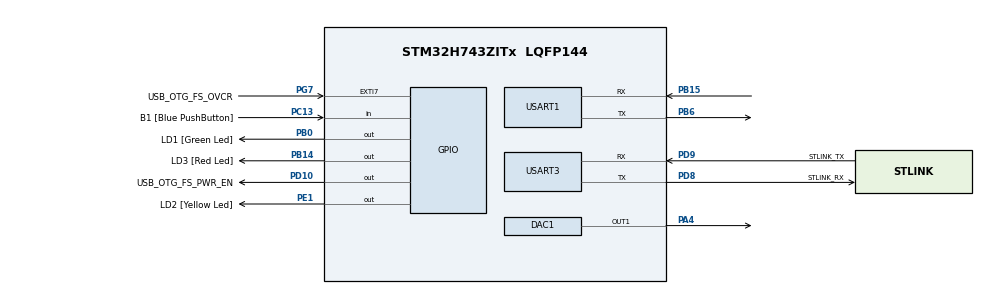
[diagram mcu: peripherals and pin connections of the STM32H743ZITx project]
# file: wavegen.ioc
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CORTEX_M7.CPU_DCache=Enabled
CORTEX_M7.CPU_ICache=Enabled
DAC1.DAC_Trigger-DAC_OUT1=DAC_TRIGGER_T6_TRGO
Dma.DAC1_CH1.0.Direction=DMA_MEMORY_TO_PERIPH
Dma.DAC1_CH1.0.EventEnable=DISABLE
Dma.DAC1_CH1.0.FIFOMode=DMA_FIFOMODE_DISABLE
Dma.DAC1_CH1.0.Instance=DMA1_Stream0
Dma.DAC1_CH1.0.MemDataAlignment=DMA_MDATAALIGN_HALFWORD
Dma.DAC1_CH1.0.MemInc=DMA_MINC_ENABLE
Dma.DAC1_CH1.0.Mode=DMA_CIRCULAR
Dma.DAC1_CH1.0.PeriphDataAlignment=DMA_PDATAALIGN_HALFWORD
Dma.DAC1_CH1.0.PeriphInc=DMA_PINC_DISABLE
Dma.DAC1_CH1.0.Polarity=HAL_DMAMUX_REQ_GEN_RISING
Dma.DAC1_CH1.0.Priority=DMA_PRIORITY_LOW
Dma.DAC1_CH1.0.RequestNumber=1
Dma.DAC1_CH1.0.SignalID=NONE
Dma.DAC1_CH1.0.SyncEnable=DISABLE
Dma.DAC1_CH1.0.SyncPolarity=HAL_DMAMUX_SYNC_NO_EVENT
Dma.DAC1_CH1.0.SyncRequestNumber=1
Dma.DAC1_CH1.0.SyncSignalID=NONE
Dma.Request0=DAC1_CH1
Mcu.Family=STM32H7
Mcu.Name=STM32H743ZITx
Mcu.Package=LQFP144
NVIC.DMA1_Stream0_IRQn=true\:0\:0\:false\:false\:true\:false\:true
NVIC.PriorityGroup=NVIC_PRIORITYGROUP_4
NVIC.TIM2_IRQn=true\:0\:0\:false\:false\:true\:false\:true
NVIC.TimeBase=TIM2_IRQn
NVIC.TimeBaseIP=TIM2
PA1.Signal=ETH_REF_CLK
PA11.Signal=USB_OTG_FS_DM
PA12.Signal=USB_OTG_FS_DP
PA2.Signal=ETH_MDIO
PA4.Signal=COMP_DAC11_group
PA7.Signal=ETH_CRS_DV
PA8.Signal=USB_OTG_FS_SOF
PA9.Signal=USB_OTG_FS_VBUS
PB0.GPIO_Label=LD1 [Green Led]
PB0.Signal=GPIO_Output
PB13.Signal=ETH_TXD1
PB14.GPIO_Label=LD3 [Red Led]
PB14.Signal=GPIO_Output
PB15.Mode=Asynchronous
PB15.Signal=USART1_RX
PB6.Mode=Asynchronous
PB6.Signal=USART1_TX
PC1.Signal=ETH_MDC
PC13.GPIO_Label=B1 [Blue PushButton]
PC13.Signal=GPIO_Input
PC14-OSC32_IN\ (OSC32_IN).Signal=RCC_OSC32_IN
PC15-OSC32_OUT\ (OSC32_OUT).Signal=RCC_OSC32_OUT
PC4.Signal=ETH_RXD0
PC5.Signal=ETH_RXD1
PD10.GPIO_Label=USB_OTG_FS_PWR_EN
PD10.Signal=GPIO_Output
PD8.GPIO_Label=STLINK_RX
PD8.Mode=Asynchronous
PD8.Signal=USART3_TX
PD9.GPIO_Label=STLINK_TX
PD9.Mode=Asynchronous
PD9.Signal=USART3_RX
PE1.GPIO_Label=LD2 [Yellow Led]
PE1.Signal=GPIO_Output
PG11.Signal=ETH_TX_EN
PG13.Signal=ETH_TXD0
PG7.GPIO_Label=USB_OTG_FS_OVCR
PG7.Signal=GPXTI7
PH0-OSC_IN\ (PH0).Mode=HSE-External-Clock-Source
PH0-OSC_IN\ (PH0).Signal=RCC_OSC_IN
PH1-OSC_OUT\ (PH1).Signal=RCC_OSC_OUT
ProjectManager.HeapSize=0x200
ProjectManager.StackSize=0x400
ProjectManager.TargetToolchain=STM32CubeIDE
RCC.ADCFreq_Value=16125000
RCC.APB1Freq_Value=100000000
RCC.APB2Freq_Value=100000000
RCC.APB3Freq_Value=100000000
RCC.APB4Freq_Value=100000000
RCC.CortexFreq_Value=400000000
RCC.D1PPRE=RCC_APB3_DIV2
RCC.D2PPRE1=RCC_APB1_DIV2
RCC.D2PPRE2=RCC_APB2_DIV2
RCC.D3PPRE=RCC_APB4_DIV2
RCC.DIVM1=4
RCC.DIVN1=400
RCC.HCLKFreq_Value=200000000
RCC.HPRE=RCC_HCLK_DIV2
RCC.HSE_VALUE=8000000
RCC.PLLSourceVirtual=RCC_PLLSOURCE_HSE
RCC.SYSCLKFreq_VALUE=400000000
RCC.SYSCLKSource=RCC_SYSCLKSOURCE_PLLCLK
RCC.USBFreq_Value=400000000
SH.COMP_DAC11_group.0=DAC1_OUT1,DAC_OUT1
TIM6.AutoReloadPreload=TIM_AUTORELOAD_PRELOAD_ENABLE
TIM6.Period=1999
TIM6.TIM_MasterOutputTrigger=TIM_TRGO_UPDATE
USART1.VirtualMode-Asynchronous=VM_ASYNC
USART3.VirtualMode-Asynchronous=VM_ASYNC
VP_SYS_VS_tim2.Mode=TIM2
VP_TIM6_VS_ClockSourceINT.Mode=Enable_Timer
board=NUCLEO-H743ZI2

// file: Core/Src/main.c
/* USER CODE BEGIN Header */
/**
  ******************************************************************************
  * @file           : main.c
  * @brief          : Main program body
  ******************************************************************************
  * @attention
  *
  * <h2><center>&copy; Copyright (c) 2020 STMicroelectronics.
  * All rights reserved.</center></h2>
  *
  * This software component is licensed by ST under BSD 3-Clause license,
  * the "License"; You may not use this file except in compliance with the
  * License. You may obtain a copy of the License at:
  *                        opensource.org/licenses/BSD-3-Clause
  *
  ******************************************************************************
  */
/* USER CODE END Header */
#include "main.h"

/* USER CODE BEGIN Includes */
#include "output.h"
#include "waves.h"
/* USER CODE END Includes */

/* USER CODE BEGIN PD */
#define WELCOME_MESSAGE			"\r\n\nDAC Waveform Project\r\n\n"
/* USER CODE END PD */

DAC_HandleTypeDef hdac1;
DMA_HandleTypeDef hdma_dac1_ch1;

TIM_HandleTypeDef htim6;

UART_HandleTypeDef huart1;
UART_HandleTypeDef huart3;

void SystemClock_Config(void);
static void MX_GPIO_Init(void);
static void MX_DMA_Init(void);
static void MX_DAC1_Init(void);
static void MX_TIM6_Init(void);
static void MX_USART1_UART_Init(void);
static void MX_USART3_UART_Init(void);

int main(void)
{

  /* Enable I-Cache---------------------------------------------------------*/
  SCB_EnableICache();

  /* Enable D-Cache---------------------------------------------------------*/
  SCB_EnableDCache();

  /* MCU Configuration--------------------------------------------------------*/

  /* Reset of all peripherals, Initializes the Flash interface and the Systick. */
  HAL_Init();

  /* Configure the system clock */
  SystemClock_Config();

  /* Initialize all configured peripherals */
  MX_GPIO_Init();
  MX_DMA_Init();
  MX_DAC1_Init();
  MX_TIM6_Init();
  MX_USART1_UART_Init();
  MX_USART3_UART_Init();
  /* USER CODE BEGIN 2 */
  output (WELCOME_MESSAGE);
  /* USER CODE END 2 */

  /* Infinite loop */
  /* USER CODE BEGIN WHILE */
  //cosine_test();
  waveforms();

  while (1)
  {
    /* USER CODE END WHILE */

  }
}

void SystemClock_Config(void)
{
  RCC_OscInitTypeDef RCC_OscInitStruct = {0};
  RCC_ClkInitTypeDef RCC_ClkInitStruct = {0};
  RCC_PeriphCLKInitTypeDef PeriphClkInitStruct = {0};

  /** Supply configuration update enable
  */
  HAL_PWREx_ConfigSupply(PWR_LDO_SUPPLY);
  /** Configure the main internal regulator output voltage
  */
  __HAL_PWR_VOLTAGESCALING_CONFIG(PWR_REGULATOR_VOLTAGE_SCALE1);

  while(!__HAL_PWR_GET_FLAG(PWR_FLAG_VOSRDY)) {}
  /** Initializes the RCC Oscillators according to the specified parameters
  * in the RCC_OscInitTypeDef structure.
  */
  RCC_OscInitStruct.OscillatorType = RCC_OSCILLATORTYPE_HSE;
  RCC_OscInitStruct.HSEState = RCC_HSE_BYPASS;
  RCC_OscInitStruct.PLL.PLLState = RCC_PLL_ON;
  RCC_OscInitStruct.PLL.PLLSource = RCC_PLLSOURCE_HSE;
  RCC_OscInitStruct.PLL.PLLM = 4;
  RCC_OscInitStruct.PLL.PLLN = 400;
  RCC_OscInitStruct.PLL.PLLP = 2;
  RCC_OscInitStruct.PLL.PLLQ = 2;
  RCC_OscInitStruct.PLL.PLLR = 2;
  RCC_OscInitStruct.PLL.PLLRGE = RCC_PLL1VCIRANGE_1;
  RCC_OscInitStruct.PLL.PLLVCOSEL = RCC_PLL1VCOWIDE;
  RCC_OscInitStruct.PLL.PLLFRACN = 0;
  if (HAL_RCC_OscConfig(&RCC_OscInitStruct) != HAL_OK)
  {
    Error_Handler();
  }
  /** Initializes the CPU, AHB and APB buses clocks
  */
  RCC_ClkInitStruct.ClockType = RCC_CLOCKTYPE_HCLK|RCC_CLOCKTYPE_SYSCLK
                              |RCC_CLOCKTYPE_PCLK1|RCC_CLOCKTYPE_PCLK2
                              |RCC_CLOCKTYPE_D3PCLK1|RCC_CLOCKTYPE_D1PCLK1;
  RCC_ClkInitStruct.SYSCLKSource = RCC_SYSCLKSOURCE_PLLCLK;
  RCC_ClkInitStruct.SYSCLKDivider = RCC_SYSCLK_DIV1;
  RCC_ClkInitStruct.AHBCLKDivider = RCC_HCLK_DIV2;
  RCC_ClkInitStruct.APB3CLKDivider = RCC_APB3_DIV2;
  RCC_ClkInitStruct.APB1CLKDivider = RCC_APB1_DIV2;
  RCC_ClkInitStruct.APB2CLKDivider = RCC_APB2_DIV2;
  RCC_ClkInitStruct.APB4CLKDivider = RCC_APB4_DIV2;

  if (HAL_RCC_ClockConfig(&RCC_ClkInitStruct, FLASH_LATENCY_2) != HAL_OK)
  {
    Error_Handler();
  }
  PeriphClkInitStruct.PeriphClockSelection = RCC_PERIPHCLK_USART3|RCC_PERIPHCLK_USART1;
  PeriphClkInitStruct.Usart234578ClockSelection = RCC_USART234578CLKSOURCE_D2PCLK1;
  PeriphClkInitStruct.Usart16ClockSelection = RCC_USART16CLKSOURCE_D2PCLK2;
  if (HAL_RCCEx_PeriphCLKConfig(&PeriphClkInitStruct) != HAL_OK)
  {
    Error_Handler();
  }
}

static void MX_DAC1_Init(void)
{

  DAC_ChannelConfTypeDef sConfig = {0};

  /** DAC Initialization
  */
  hdac1.Instance = DAC1;
  if (HAL_DAC_Init(&hdac1) != HAL_OK)
  {
    Error_Handler();
  }
  /** DAC channel OUT1 config
  */
  sConfig.DAC_SampleAndHold = DAC_SAMPLEANDHOLD_DISABLE;
  sConfig.DAC_Trigger = DAC_TRIGGER_T6_TRGO;
  sConfig.DAC_OutputBuffer = DAC_OUTPUTBUFFER_ENABLE;
  sConfig.DAC_ConnectOnChipPeripheral = DAC_CHIPCONNECT_DISABLE;
  sConfig.DAC_UserTrimming = DAC_TRIMMING_FACTORY;
  if (HAL_DAC_ConfigChannel(&hdac1, &sConfig, DAC_CHANNEL_1) != HAL_OK)
  {
    Error_Handler();
  }

}

static void MX_TIM6_Init(void)
{

  TIM_MasterConfigTypeDef sMasterConfig = {0};

  htim6.Instance = TIM6;
  htim6.Init.Prescaler = 0;
  htim6.Init.CounterMode = TIM_COUNTERMODE_UP;
  htim6.Init.Period = 1999;
  htim6.Init.AutoReloadPreload = TIM_AUTORELOAD_PRELOAD_ENABLE;
  if (HAL_TIM_Base_Init(&htim6) != HAL_OK)
  {
    Error_Handler();
  }
  sMasterConfig.MasterOutputTrigger = TIM_TRGO_UPDATE;
  sMasterConfig.MasterSlaveMode = TIM_MASTERSLAVEMODE_DISABLE;
  if (HAL_TIMEx_MasterConfigSynchronization(&htim6, &sMasterConfig) != HAL_OK)
  {
    Error_Handler();
  }
  /* USER CODE BEGIN TIM6_Init 2 */
  /*##-2- Enable TIM peripheral counter ######################################*/
  HAL_TIM_Base_Start (&htim6);
  /* USER CODE END TIM6_Init 2 */

}

static void MX_USART1_UART_Init(void)
{

  huart1.Instance = USART1;
  huart1.Init.BaudRate = 115200;
  huart1.Init.WordLength = UART_WORDLENGTH_8B;
  huart1.Init.StopBits = UART_STOPBITS_1;
  huart1.Init.Parity = UART_PARITY_NONE;
  huart1.Init.Mode = UART_MODE_TX_RX;
  huart1.Init.HwFlowCtl = UART_HWCONTROL_NONE;
  huart1.Init.OverSampling = UART_OVERSAMPLING_16;
  huart1.Init.OneBitSampling = UART_ONE_BIT_SAMPLE_DISABLE;
  huart1.Init.ClockPrescaler = UART_PRESCALER_DIV1;
  huart1.AdvancedInit.AdvFeatureInit = UART_ADVFEATURE_NO_INIT;
  if (HAL_UART_Init(&huart1) != HAL_OK)
  {
    Error_Handler();
  }
  if (HAL_UARTEx_SetTxFifoThreshold(&huart1, UART_TXFIFO_THRESHOLD_1_8) != HAL_OK)
  {
    Error_Handler();
  }
  if (HAL_UARTEx_SetRxFifoThreshold(&huart1, UART_RXFIFO_THRESHOLD_1_8) != HAL_OK)
  {
    Error_Handler();
  }
  if (HAL_UARTEx_DisableFifoMode(&huart1) != HAL_OK)
  {
    Error_Handler();
  }

}

static void MX_USART3_UART_Init(void)
{

  huart3.Instance = USART3;
  huart3.Init.BaudRate = 115200;
  huart3.Init.WordLength = UART_WORDLENGTH_8B;
  huart3.Init.StopBits = UART_STOPBITS_1;
  huart3.Init.Parity = UART_PARITY_NONE;
  huart3.Init.Mode = UART_MODE_TX_RX;
  huart3.Init.HwFlowCtl = UART_HWCONTROL_NONE;
  huart3.Init.OverSampling = UART_OVERSAMPLING_16;
  huart3.Init.OneBitSampling = UART_ONE_BIT_SAMPLE_DISABLE;
  huart3.Init.ClockPrescaler = UART_PRESCALER_DIV1;
  huart3.AdvancedInit.AdvFeatureInit = UART_ADVFEATURE_NO_INIT;
  if (HAL_UART_Init(&huart3) != HAL_OK)
  {
    Error_Handler();
  }
  if (HAL_UARTEx_SetTxFifoThreshold(&huart3, UART_TXFIFO_THRESHOLD_1_8) != HAL_OK)
  {
    Error_Handler();
  }
  if (HAL_UARTEx_SetRxFifoThreshold(&huart3, UART_RXFIFO_THRESHOLD_1_8) != HAL_OK)
  {
    Error_Handler();
  }
  if (HAL_UARTEx_DisableFifoMode(&huart3) != HAL_OK)
  {
    Error_Handler();
  }

}

static void MX_DMA_Init(void)
{

  /* DMA controller clock enable */
  __HAL_RCC_DMA1_CLK_ENABLE();

  /* DMA interrupt init */
  /* DMA1_Stream0_IRQn interrupt configuration */
  HAL_NVIC_SetPriority(DMA1_Stream0_IRQn, 0, 0);
  HAL_NVIC_EnableIRQ(DMA1_Stream0_IRQn);

}

static void MX_GPIO_Init(void)
{
  GPIO_InitTypeDef GPIO_InitStruct = {0};

  /* GPIO Ports Clock Enable */
  __HAL_RCC_GPIOC_CLK_ENABLE();
  __HAL_RCC_GPIOH_CLK_ENABLE();
  __HAL_RCC_GPIOA_CLK_ENABLE();
  __HAL_RCC_GPIOB_CLK_ENABLE();
  __HAL_RCC_GPIOD_CLK_ENABLE();
  __HAL_RCC_GPIOG_CLK_ENABLE();
  __HAL_RCC_GPIOE_CLK_ENABLE();

  /*Configure GPIO pin Output Level */
  HAL_GPIO_WritePin(GPIOB, LD1_Pin|LD3_Pin, GPIO_PIN_RESET);

  /*Configure GPIO pin Output Level */
  HAL_GPIO_WritePin(USB_OTG_FS_PWR_EN_GPIO_Port, USB_OTG_FS_PWR_EN_Pin, GPIO_PIN_RESET);

  /*Configure GPIO pin Output Level */
  HAL_GPIO_WritePin(LD2_GPIO_Port, LD2_Pin, GPIO_PIN_RESET);

  /*Configure GPIO pin : B1_Pin */
  GPIO_InitStruct.Pin = B1_Pin;
  GPIO_InitStruct.Mode = GPIO_MODE_INPUT;
  GPIO_InitStruct.Pull = GPIO_NOPULL;
  HAL_GPIO_Init(B1_GPIO_Port, &GPIO_InitStruct);

  /*Configure GPIO pins : PC1 PC4 PC5 */
  GPIO_InitStruct.Pin = GPIO_PIN_1|GPIO_PIN_4|GPIO_PIN_5;
  GPIO_InitStruct.Mode = GPIO_MODE_AF_PP;
  GPIO_InitStruct.Pull = GPIO_NOPULL;
  GPIO_InitStruct.Speed = GPIO_SPEED_FREQ_LOW;
  GPIO_InitStruct.Alternate = GPIO_AF11_ETH;
  HAL_GPIO_Init(GPIOC, &GPIO_InitStruct);

  /*Configure GPIO pins : PA1 PA2 PA7 */
  GPIO_InitStruct.Pin = GPIO_PIN_1|GPIO_PIN_2|GPIO_PIN_7;
  GPIO_InitStruct.Mode = GPIO_MODE_AF_PP;
  GPIO_InitStruct.Pull = GPIO_NOPULL;
  GPIO_InitStruct.Speed = GPIO_SPEED_FREQ_LOW;
  GPIO_InitStruct.Alternate = GPIO_AF11_ETH;
  HAL_GPIO_Init(GPIOA, &GPIO_InitStruct);

  /*Configure GPIO pins : LD1_Pin LD3_Pin */
  GPIO_InitStruct.Pin = LD1_Pin|LD3_Pin;
  GPIO_InitStruct.Mode = GPIO_MODE_OUTPUT_PP;
  GPIO_InitStruct.Pull = GPIO_NOPULL;
  GPIO_InitStruct.Speed = GPIO_SPEED_FREQ_LOW;
  HAL_GPIO_Init(GPIOB, &GPIO_InitStruct);

  /*Configure GPIO pin : PB13 */
  GPIO_InitStruct.Pin = GPIO_PIN_13;
  GPIO_InitStruct.Mode = GPIO_MODE_AF_PP;
  GPIO_InitStruct.Pull = GPIO_NOPULL;
  GPIO_InitStruct.Speed = GPIO_SPEED_FREQ_LOW;
  GPIO_InitStruct.Alternate = GPIO_AF11_ETH;
  HAL_GPIO_Init(GPIOB, &GPIO_InitStruct);

  /*Configure GPIO pin : USB_OTG_FS_PWR_EN_Pin */
  GPIO_InitStruct.Pin = USB_OTG_FS_PWR_EN_Pin;
  GPIO_InitStruct.Mode = GPIO_MODE_OUTPUT_PP;
  GPIO_InitStruct.Pull = GPIO_NOPULL;
  GPIO_InitStruct.Speed = GPIO_SPEED_FREQ_LOW;
  HAL_GPIO_Init(USB_OTG_FS_PWR_EN_GPIO_Port, &GPIO_InitStruct);

  /*Configure GPIO pin : USB_OTG_FS_OVCR_Pin */
  GPIO_InitStruct.Pin = USB_OTG_FS_OVCR_Pin;
  GPIO_InitStruct.Mode = GPIO_MODE_IT_RISING;
  GPIO_InitStruct.Pull = GPIO_NOPULL;
  HAL_GPIO_Init(USB_OTG_FS_OVCR_GPIO_Port, &GPIO_InitStruct);

  /*Configure GPIO pins : PA8 PA11 PA12 */
  GPIO_InitStruct.Pin = GPIO_PIN_8|GPIO_PIN_11|GPIO_PIN_12;
  GPIO_InitStruct.Mode = GPIO_MODE_AF_PP;
  GPIO_InitStruct.Pull = GPIO_NOPULL;
  GPIO_InitStruct.Speed = GPIO_SPEED_FREQ_LOW;
  GPIO_InitStruct.Alternate = GPIO_AF10_OTG1_FS;
  HAL_GPIO_Init(GPIOA, &GPIO_InitStruct);

  /*Configure GPIO pins : PG11 PG13 */
  GPIO_InitStruct.Pin = GPIO_PIN_11|GPIO_PIN_13;
  GPIO_InitStruct.Mode = GPIO_MODE_AF_PP;
  GPIO_InitStruct.Pull = GPIO_NOPULL;
  GPIO_InitStruct.Speed = GPIO_SPEED_FREQ_LOW;
  GPIO_InitStruct.Alternate = GPIO_AF11_ETH;
  HAL_GPIO_Init(GPIOG, &GPIO_InitStruct);

  /*Configure GPIO pin : LD2_Pin */
  GPIO_InitStruct.Pin = LD2_Pin;
  GPIO_InitStruct.Mode = GPIO_MODE_OUTPUT_PP;
  GPIO_InitStruct.Pull = GPIO_NOPULL;
  GPIO_InitStruct.Speed = GPIO_SPEED_FREQ_LOW;
  HAL_GPIO_Init(LD2_GPIO_Port, &GPIO_InitStruct);

}

 /**
  * @brief  Period elapsed callback in non blocking mode
  * @note   This function is called  when TIM2 interrupt took place, inside
  * HAL_TIM_IRQHandler(). It makes a direct call to HAL_IncTick() to increment
  * a global variable "uwTick" used as application time base.
  * @param  htim : TIM handle
  * @retval None
  */
void HAL_TIM_PeriodElapsedCallback(TIM_HandleTypeDef *htim)
{
  if (htim->Instance == TIM2) {
    HAL_IncTick();
  }
}

void Error_Handler(void)
{
  __disable_irq();
  while (1)
  {
  }
}

/************************ (C) COPYRIGHT STMicroelectronics *****END OF FILE****/
